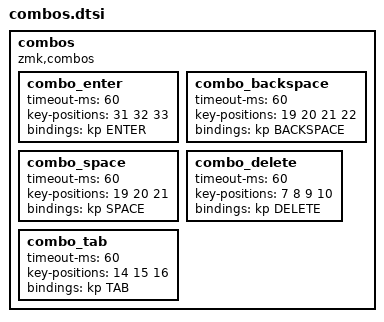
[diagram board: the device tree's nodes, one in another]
combos {
    compatible = "zmk,combos";
    /* right hand */
    combo_enter {
        timeout-ms = <60>;
        key-positions = <31 32 33>;
        bindings = <&kp ENTER>;
    };
    combo_backspace {
        timeout-ms = <60>;
        key-positions = <19 20 21 22>;
        bindings = <&kp BACKSPACE>;
    };
    combo_space {
        timeout-ms = <60>;
        key-positions = <19 20 21>;
        bindings = <&kp SPACE>;
    };
    
    /* left hand */
    combo_delete {
        timeout-ms = <60>;
        key-positions = <7 8 9 10>;
        bindings = <&kp DELETE>;
    };
    combo_tab {
        timeout-ms = <60>;
        key-positions = <14 15 16>;
        bindings = <&kp TAB>;
    };
};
